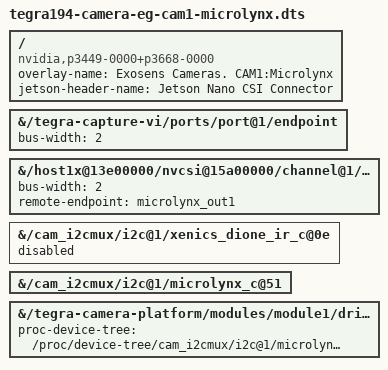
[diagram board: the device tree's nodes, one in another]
// SPDX-License-Identifier: GPL-2.0-only

/dts-v1/;
/plugin/;

/ {
	overlay-name = "Exosens Cameras. CAM1:Microlynx";
	jetson-header-name = "Jetson Nano CSI Connector";
	compatible = "nvidia,p3449-0000+p3668-0000", "nvidia,p3449-0000+p3668-0001", "nvidia,p3509-0000+p3668-0000", "nvidia,p3509-0000+p3668-0001";

	fragment@10 {
		target-path = "/tegra-capture-vi/ports/port@1/endpoint";
		__overlay__ {
			bus-width=<2>;
		};
	};

	fragment@11 {
		target-path = "/host1x@13e00000/nvcsi@15a00000/channel@1/ports/port@0/endpoint@2";
		__overlay__ {
			bus-width=<2>;
			remote-endpoint = <&microlynx_out1>;
		};
	};

	// Disable Dione cameras
	fragment@12 {
		target-path = "/cam_i2cmux/i2c@1/xenics_dione_ir_c@0e";
		__overlay__ {
			status = "disabled";
		};
	};

	// Enable Microlynx
	fragment@13 {
		target-path = "/cam_i2cmux/i2c@1/microlynx_c@51";
		__overlay__ {
			status = "okay";
		};
	};

	fragment@14 {
		target-path = "/tegra-camera-platform/modules/module1/drivernode0";
		__overlay__ {
			proc-device-tree = "/proc/device-tree/cam_i2cmux/i2c@1/microlynx_c@51";
		};
	};

};
